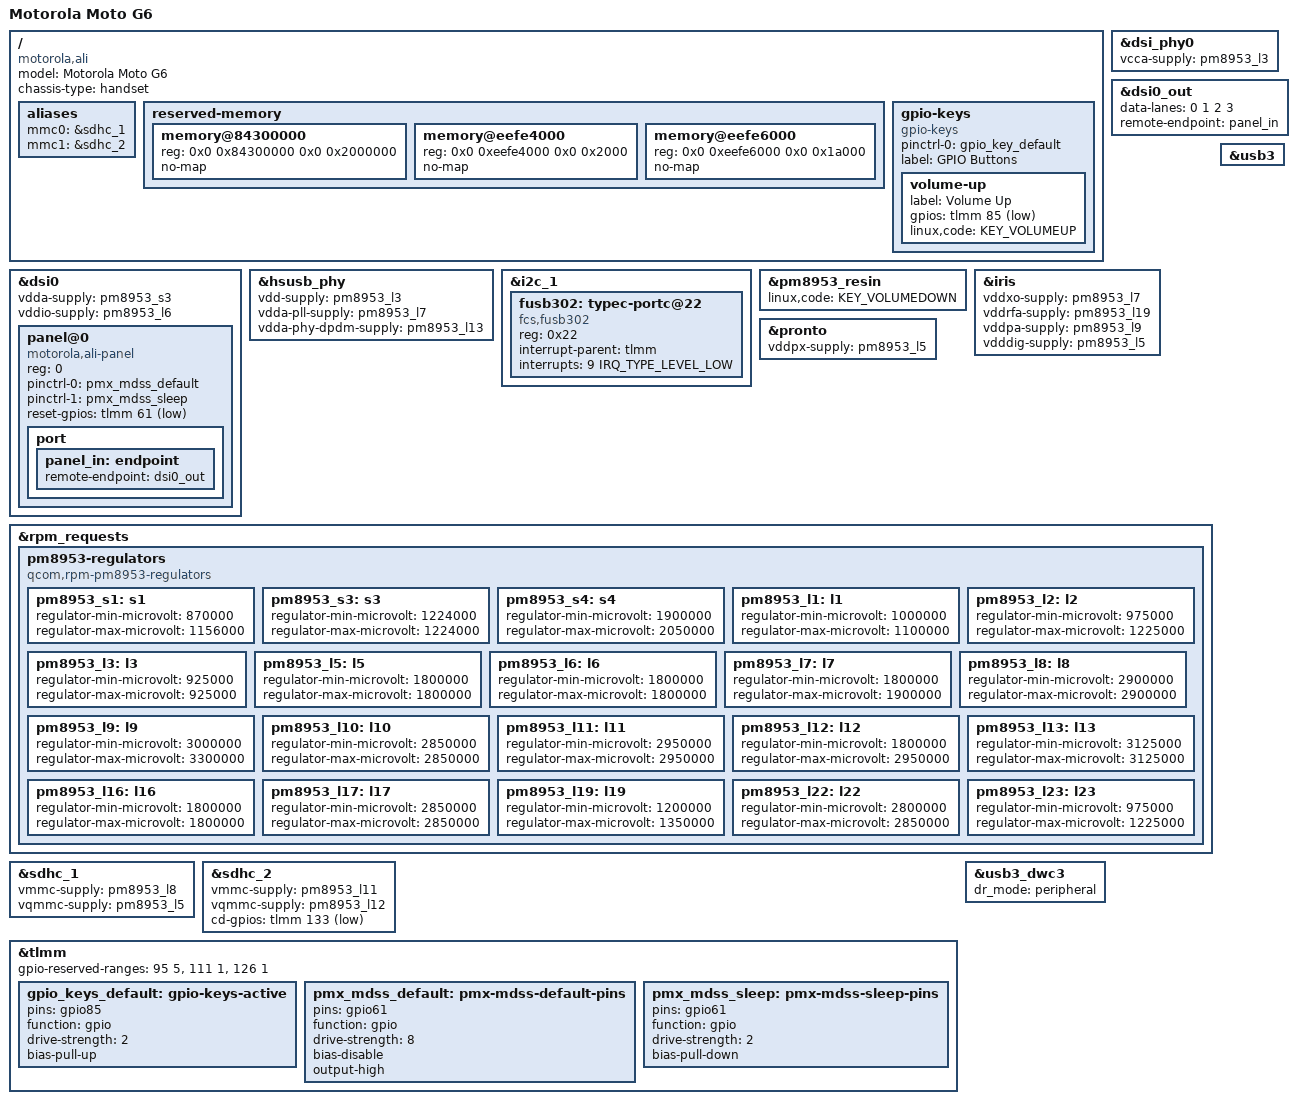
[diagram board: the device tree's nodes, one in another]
// SPDX-License-Identifier: BSD-3-Clause
// Copyright (c) 2022, The Linux Foundation. All rights reserved.

/dts-v1/;

#include "msm8953.dtsi"
#include "pm8953.dtsi"
#include <dt-bindings/input/input.h>

/ {
	model = "Motorola Moto G6";
	compatible = "motorola,ali", "qcom,sdm450";
	chassis-type = "handset";


	aliases {
		mmc0 = &sdhc_1;
		mmc1 = &sdhc_2;
	};

	reserved-memory {
		/delete-node/memory@85b00000;

		memory@84300000 {
			reg = <0x0 0x84300000 0x0 0x2000000>;
			no-map;
		};

		memory@eefe4000 {
			reg = <0x0 0xeefe4000 0x0 0x2000>;
			no-map;
		};

		memory@eefe6000 {
			reg = <0x0 0xeefe6000 0x0 0x1a000>;
			no-map;
		};
	};

  	gpio-keys {
		compatible = "gpio-keys";

		pinctrl-names = "default";
		pinctrl-0 = <&gpio_key_default>;

		label = "GPIO Buttons";

		volume-up {
			label = "Volume Up";
			gpios = <&tlmm 85 GPIO_ACTIVE_LOW>;
			linux,code = <KEY_VOLUMEUP>;
		};
	};
};

&dsi_phy0 {
	vcca-supply = <&pm8953_l3>;
};

&dsi0_out {
	data-lanes = <0 1 2 3>;
	remote-endpoint = <&panel_in>;
};

&dsi0 {
	status = "okay";

	vdda-supply = <&pm8953_s3>;
	vddio-supply = <&pm8953_l6>;

	panel@0 {
		compatible = "motorola,ali-panel";
		reg = <0>;

		pinctrl-names = "default", "sleep";
		pinctrl-0 = <&pmx_mdss_default>;
		pinctrl-1 = <&pmx_mdss_sleep>;

		reset-gpios = <&tlmm 61 GPIO_ACTIVE_LOW>;

		port {
			panel_in: endpoint {
				remote-endpoint = <&dsi0_out>;
			};
		};
	};
};

&hsusb_phy {
	status = "okay";

	vdd-supply = <&pm8953_l3>;
	vdda-pll-supply = <&pm8953_l7>;
	vdda-phy-dpdm-supply = <&pm8953_l13>;
};

&i2c_1 {
	status = "okay";

	fusb302: typec-portc@22 {
		compatible = "fcs,fusb302";
		reg = <0x22>;
		interrupt-parent = <&tlmm>;
		interrupts = <9 IRQ_TYPE_LEVEL_LOW>;
		// FIXME: supply-vbus property

		// FIXME: connector node
	};
};

&pm8953_resin {
	status = "okay";
	linux,code = <KEY_VOLUMEDOWN>;
};

&iris {
	vddxo-supply = <&pm8953_l7>;
	vddrfa-supply = <&pm8953_l19>;
	vddpa-supply = <&pm8953_l9>;
	vdddig-supply = <&pm8953_l5>;
};

&pronto {
	status = "okay";

	vddpx-supply = <&pm8953_l5>;
};

&rpm_requests {
	pm8953-regulators {
		compatible = "qcom,rpm-pm8953-regulators";

		// FIXME: Supplies

		pm8953_s1: s1 {
			regulator-min-microvolt = <870000>;
			regulator-max-microvolt = <1156000>;
		};
		pm8953_s3: s3 {
			regulator-min-microvolt = <1224000>;
			regulator-max-microvolt = <1224000>;
		};
		pm8953_s4: s4 {
			regulator-min-microvolt = <1900000>;
			regulator-max-microvolt = <2050000>;
		};
		pm8953_l1: l1 {
			regulator-min-microvolt = <1000000>;
			regulator-max-microvolt = <1100000>;
		};
		pm8953_l2: l2 {
			regulator-min-microvolt = <975000>;
			regulator-max-microvolt = <1225000>;
		};
		pm8953_l3: l3 {
			regulator-min-microvolt = <925000>;
			regulator-max-microvolt = <925000>;
		};
		pm8953_l5: l5 {
			regulator-min-microvolt = <1800000>;
			regulator-max-microvolt = <1800000>;
		};
		pm8953_l6: l6 {
			regulator-min-microvolt = <1800000>;
			regulator-max-microvolt = <1800000>;
		};
		pm8953_l7: l7 {
			regulator-min-microvolt = <1800000>;
			regulator-max-microvolt = <1900000>;
		};
		pm8953_l8: l8 {
			regulator-min-microvolt = <2900000>;
			regulator-max-microvolt = <2900000>;
		};
		pm8953_l9: l9 {
			regulator-min-microvolt = <3000000>;
			regulator-max-microvolt = <3300000>;
		};
		pm8953_l10: l10 {
			regulator-min-microvolt = <2850000>;
			regulator-max-microvolt = <2850000>;
		};
		pm8953_l11: l11 {
			regulator-min-microvolt = <2950000>;
			regulator-max-microvolt = <2950000>;
		};
		pm8953_l12: l12 {
			regulator-min-microvolt = <1800000>;
			regulator-max-microvolt = <2950000>;
		};
		pm8953_l13: l13 {
			regulator-min-microvolt = <3125000>;
			regulator-max-microvolt = <3125000>;
		};
		pm8953_l16: l16 {
			regulator-min-microvolt = <1800000>;
			regulator-max-microvolt = <1800000>;
		};
		pm8953_l17: l17 {
			regulator-min-microvolt = <2850000>;
			regulator-max-microvolt = <2850000>;
		};
		pm8953_l19: l19 {
			regulator-min-microvolt = <1200000>;
			regulator-max-microvolt = <1350000>;
		};
		pm8953_l22: l22 {
			regulator-min-microvolt = <2800000>;
			regulator-max-microvolt = <2850000>;
		};
		pm8953_l23: l23 {
			regulator-min-microvolt = <975000>;
			regulator-max-microvolt = <1225000>;
		};
	};
};

&sdhc_1 {
	status = "okay";

	vmmc-supply = <&pm8953_l8>;
	vqmmc-supply = <&pm8953_l5>;
};

&sdhc_2 {
	status = "okay";

	vmmc-supply = <&pm8953_l11>;
	vqmmc-supply = <&pm8953_l12>;

	cd-gpios = <&tlmm 133 GPIO_ACTIVE_LOW>;
};

&tlmm {
	gpio-reserved-ranges = <95 5>, <111 1>, <126 1>;

	gpio_keys_default: gpio-keys-active {
		pins = "gpio85";
		function = "gpio";
		drive-strength = <2>;
		bias-pull-up;
	};

	pmx_mdss_default: pmx-mdss-default-pins {
		pins = "gpio61";
		function = "gpio";
		drive-strength = <8>;
		bias-disable;
		output-high;
	};

	pmx_mdss_sleep: pmx-mdss-sleep-pins {
		pins = "gpio61";
		function = "gpio";
		drive-strength = <2>;
		bias-pull-down;
	};
};

&usb3 {
	status = "okay";
};

&usb3_dwc3 {
	dr_mode = "peripheral";
};
